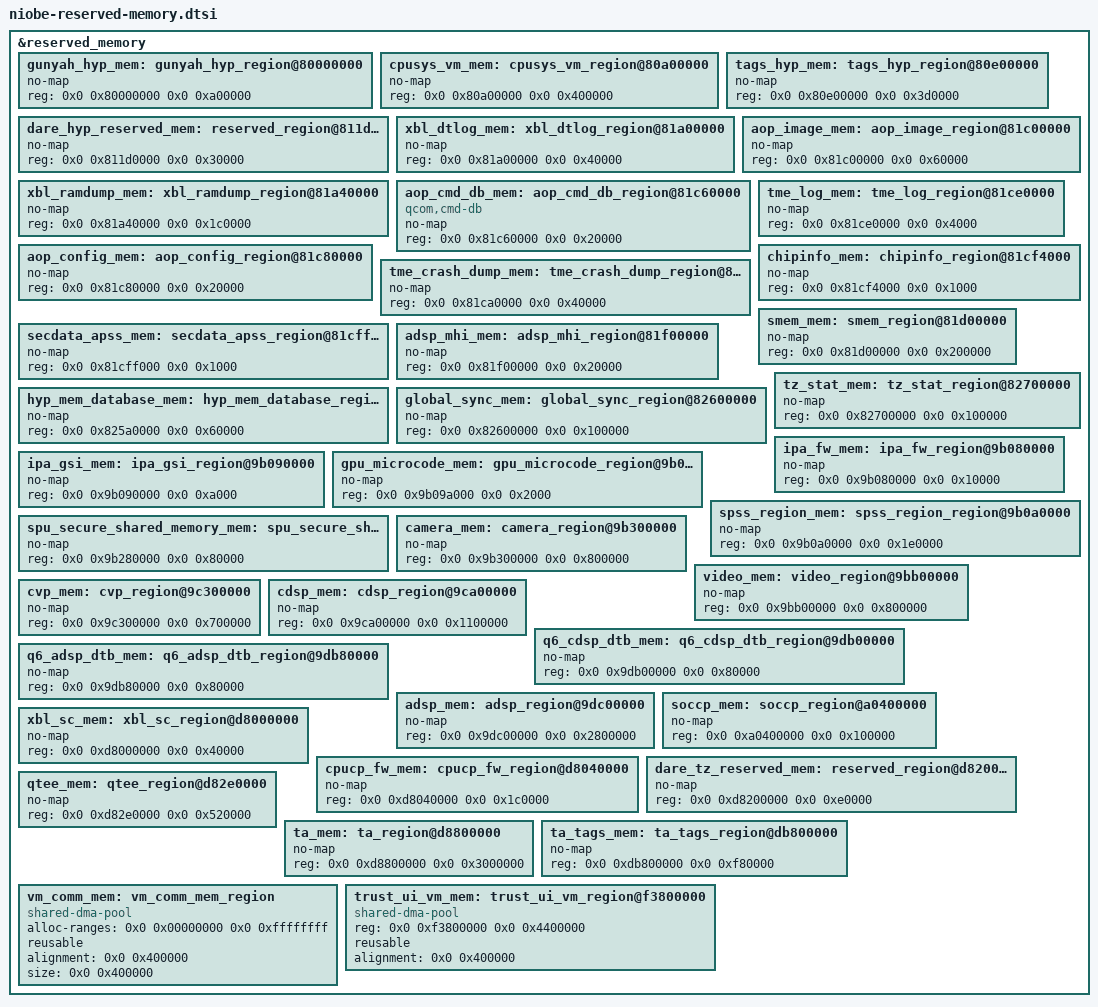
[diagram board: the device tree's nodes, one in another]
&reserved_memory {
	#address-cells = <2>;
	#size-cells = <2>;
	ranges;

	gunyah_hyp_mem: gunyah_hyp_region@80000000 {
		no-map;
		reg = <0x0 0x80000000 0x0 0xa00000>;
	};

	cpusys_vm_mem: cpusys_vm_region@80a00000 {
		no-map;
		reg = <0x0 0x80a00000 0x0 0x400000>;
	};

	tags_hyp_mem: tags_hyp_region@80e00000 {
		no-map;
		reg = <0x0 0x80e00000 0x0 0x3d0000>;
	};

	dare_hyp_reserved_mem: reserved_region@811d0000 {
		no-map;
		reg = <0x0 0x811d0000 0x0 0x30000>;
	};

	xbl_dtlog_mem: xbl_dtlog_region@81a00000 {
		no-map;
		reg = <0x0 0x81a00000 0x0 0x40000>;
	};

	xbl_ramdump_mem: xbl_ramdump_region@81a40000 {
		no-map;
		reg = <0x0 0x81a40000 0x0 0x1c0000>;
	};

	aop_image_mem: aop_image_region@81c00000 {
		no-map;
		reg = <0x0 0x81c00000 0x0 0x60000>;
	};

	aop_cmd_db_mem: aop_cmd_db_region@81c60000 {
		compatible = "qcom,cmd-db";
		no-map;
		reg = <0x0 0x81c60000 0x0 0x20000>;
	};

	aop_config_mem: aop_config_region@81c80000 {
		no-map;
		reg = <0x0 0x81c80000 0x0 0x20000>;
	};

	tme_crash_dump_mem: tme_crash_dump_region@81ca0000 {
		no-map;
		reg = <0x0 0x81ca0000 0x0 0x40000>;
	};

	tme_log_mem: tme_log_region@81ce0000 {
		no-map;
		reg = <0x0 0x81ce0000 0x0 0x4000>;
	};

	/* UEFI region at 0x81ce4000 is reclaimed by Linux */

	chipinfo_mem: chipinfo_region@81cf4000 {
		no-map;
		reg = <0x0 0x81cf4000 0x0 0x1000>;
	};

	secdata_apss_mem: secdata_apss_region@81cff000 {
		no-map;
		reg = <0x0 0x81cff000 0x0 0x1000>;
	};

	smem_mem: smem_region@81d00000 {
		no-map;
		reg = <0x0 0x81d00000 0x0 0x200000>;
	};

	adsp_mhi_mem: adsp_mhi_region@81f00000 {
		no-map;
		reg = <0x0 0x81f00000 0x0 0x20000>;
	};

	hyp_mem_database_mem: hyp_mem_database_region@825a0000 {
		no-map;
		reg = <0x0 0x825a0000 0x0 0x60000>;
	};

	global_sync_mem: global_sync_region@82600000 {
		no-map;
		reg = <0x0 0x82600000 0x0 0x100000>;
	};

	tz_stat_mem: tz_stat_region@82700000 {
		no-map;
		reg = <0x0 0x82700000 0x0 0x100000>;
	};

	ipa_fw_mem: ipa_fw_region@9b080000 {
		no-map;
		reg = <0x0 0x9b080000 0x0 0x10000>;
	};

	ipa_gsi_mem: ipa_gsi_region@9b090000 {
		no-map;
		reg = <0x0 0x9b090000 0x0 0xa000>;
	};

	gpu_microcode_mem: gpu_microcode_region@9b09a000 {
		no-map;
		reg = <0x0 0x9b09a000 0x0 0x2000>;
	};

	spss_region_mem: spss_region_region@9b0a0000 {
		no-map;
		reg = <0x0 0x9b0a0000 0x0 0x1e0000>;
	};

	spu_secure_shared_memory_mem: spu_secure_shared_memory_region@9b280000 {
		no-map;
		reg = <0x0 0x9b280000 0x0 0x80000>;
	};

	camera_mem: camera_region@9b300000 {
		no-map;
		reg = <0x0 0x9b300000 0x0 0x800000>;
	};

	video_mem: video_region@9bb00000 {
		no-map;
		reg = <0x0 0x9bb00000 0x0 0x800000>;
	};

	cvp_mem: cvp_region@9c300000 {
		no-map;
		reg = <0x0 0x9c300000 0x0 0x700000>;
	};

	cdsp_mem: cdsp_region@9ca00000 {
		no-map;
		reg = <0x0 0x9ca00000 0x0 0x1100000>;
	};

	q6_cdsp_dtb_mem: q6_cdsp_dtb_region@9db00000 {
		no-map;
		reg = <0x0 0x9db00000 0x0 0x80000>;
	};

	q6_adsp_dtb_mem: q6_adsp_dtb_region@9db80000 {
		no-map;
		reg = <0x0 0x9db80000 0x0 0x80000>;
	};

	adsp_mem: adsp_region@9dc00000 {
		no-map;
		reg = <0x0 0x9dc00000 0x0 0x2800000>;
	};

	soccp_mem: soccp_region@a0400000 {
		no-map;
		reg = <0x0 0xa0400000 0x0 0x100000>;
	};

	/* UEFI region at 0xa7000000 is reclaimed by Linux */

	/* Linux kernel image is loaded at 0xa8000000 */

	xbl_sc_mem: xbl_sc_region@d8000000 {
		no-map;
		reg = <0x0 0xd8000000 0x0 0x40000>;
	};

	cpucp_fw_mem: cpucp_fw_region@d8040000 {
		no-map;
		reg = <0x0 0xd8040000 0x0 0x1c0000>;
	};

	dare_tz_reserved_mem: reserved_region@d8200000 {
		no-map;
		reg = <0x0 0xd8200000 0x0 0xe0000>;
	};

	qtee_mem: qtee_region@d82e0000 {
		no-map;
		reg = <0x0 0xd82e0000 0x0 0x520000>;
	};

	ta_mem: ta_region@d8800000 {
		no-map;
		reg = <0x0 0xd8800000 0x0 0x3000000>;
	};

	ta_tags_mem: ta_tags_region@db800000 {
		no-map;
		reg = <0x0 0xdb800000 0x0 0xf80000>;
	};

	vm_comm_mem: vm_comm_mem_region {
		compatible = "shared-dma-pool";
		alloc-ranges = <0x0 0x00000000 0x0 0xffffffff>;
		reusable;
		alignment = <0x0 0x400000>;
		size = <0x0 0x400000>;
	};

	trust_ui_vm_mem: trust_ui_vm_region@f3800000 {
		compatible = "shared-dma-pool";
		reg = <0x0 0xf3800000 0x0 0x4400000>;
		reusable;
		alignment = <0x0 0x400000>;
	};

};
